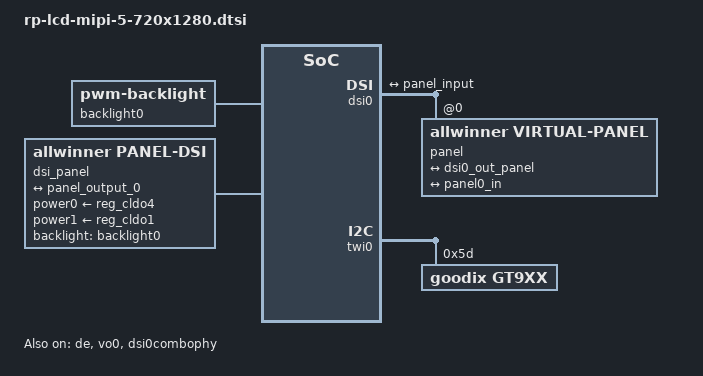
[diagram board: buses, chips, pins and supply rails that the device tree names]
/{
    backlight0: backlight@0 {
        compatible = "pwm-backlight";
        status = "okay";
        brightness-levels = <
              0   1   2   3   4   5   6   7
              8   9  10  11  12  13  14  15
             16  17  18  19  20  21  22  23
             24  25  26  27  28  29  30  31
             32  33  34  35  36  37  38  39
             40  41  42  43  44  45  46  47
             48  49  50  51  52  53  54  55
             56  57  58  59  60  61  62  63
             64  65  66  67  68  69  70  71
             72  73  74  75  76  77  78  79
             80  81  82  83  84  85  86  87
             88  89  90  91  92  93  94  95
             96  97  98  99 100 101 102 103
            104 105 106 107 108 109 110 111
            112 113 114 115 116 117 118 119
            120 121 122 123 124 125 126 127
            128 129 130 131 132 133 134 135
            136 137 138 139 140 141 142 143
            144 145 146 147 148 149 150 151
            152 153 154 155 156 157 158 159
            160 161 162 163 164 165 166 167
            168 169 170 171 172 173 174 175
            176 177 178 179 180 181 182 183
            184 185 186 187 188 189 190 191
            192 193 194 195 196 197 198 199
            200 201 202 203 204 205 206 207
            208 209 210 211 212 213 214 215
            216 217 218 219 220 221 222 223
            224 225 226 227 228 229 230 231
            232 233 234 235 236 237 238 239
            240 241 242 243 244 245 246 247
            248 249 250 251 252 253 254 255>;
        default-brightness-level = <200>;
        // pwms = <&pwm2 0 50000 0>; // config in lcd-gpio-xxx.dtsi
    };

    dsi_panel: dsi_panel@0 {
        compatible = "allwinner,panel-dsi";
        status = "okay";
        reg = <0>;
        power0-supply = <&reg_cldo4>;
        power1-supply = <&reg_cldo1>;

        // reset-gpios = <&pio PJ 17 GPIO_ACTIVE_HIGH>;   // config in lcd-gpio-xxx.dtsi
        // enable0-gpios = <&pio PJ 16 GPIO_ACTIVE_HIGH>; // config in lcd-gpio-xxx.dtsi
        power-delay-ms = <20>;
        enable-delay-ms = <20>;
        reset-num = <1>;
        reset-delay-ms = <20>;

        backlight = <&backlight0>;
        dsi,flags = <MIPI_DSI_MODE_VIDEO>;
        dsi,lanes = <4>;
        dsi,format = <0>; //MIPI_DSI_FMT_RGB888
        panel-init-sequence = [
            39 00 04 B9 F1 12 83
            39 00 0B B3 07 0B 1E 1E 03 FF 00 00 00 00
            39 00 02 BC 46
            39 00 02 CC 0B
            39 00 02 B4 80
            39 00 04 B2 C8 12 A0
            39 00 0F E3 07 07 0B 0B 03 0B 00 00 00 00 FF 80 C0 10
            39 00 0D C1 53 00 32 32 77 F1 FF FF CC CC 77 77
            39 00 03 B5 09 09
            39 00 03 B6 B7 B7
            39 00 40 E9 C2 10 0A 00 00 81 80 12 30 00 37 86 81 80 37 18 00 05 00 00 00 00 00 05 00 00 00 00 F8 BA 46 02 08 28 88 88 88 88 88 F8 BA 57 13 18 38 88 88 88 88 88 00 00 00 03 00 00 00 00 00 00 00 00 00
            39 00 3E EA 07 12 01 01 02 3C 00 00 00 00 00 00 8F BA 31 75 38 18 88 88 88 88 88 8F BA 20 64 28 08 88 88 88 88 88 23 10 00 00 04 00 00 00 00 00 00 00 00 00 00 00 00 00 00 00 00 00 00 00 00 00 00
            39 00 23 E0 00 02 04 1A 23 3F 2C 28 05 09 0B 10 11 10 12 12 19 00 02 04 1A 23 3F 2C 28 05 09 0B 10 11 10 12 12 19
            05 78 01 11
            05 00 01 29
        ];

        panel-exit-sequence = [
            05 14 01 28
            05 50 01 10
        ];

        display-timings {
            native-mode = <&dsi0_timing0>;

            dsi0_timing0: timing0 {
                clock-frequency = <75000000>; /* pixel clock */
                hactive      = <720>;
                hback-porch  = <45>;
                hfront-porch = <136>;
                hsync-len    = <10>;

                vactive      = <1280>;
                vback-porch  = <216>;
                vfront-porch = <16>;
                vsync-len    = <10>;
            };
        };
        port {
            panel0_in: endpoint@0 {
                reg = <0>;
                    remote-endpoint = <&panel_output_0>;
            };
        };
    };
};

&lvds0 {
    status = "disabled";
};

&dsi0 {
    status = "okay";
    pinctrl-0 = <&dsi0_4lane_pins_a>;
    pinctrl-1 = <&dsi0_4lane_pins_b>;
    pinctrl-names = "active","sleep";
    ports {
        dsi0_out: port@1{
            dsi0_out_panel: endpoint {
                remote-endpoint = <&panel_input>;
            };
        };
    };
    panel: panel@0 {
        compatible = "allwinner,virtual-panel";
        status = "okay";
        reg = <0>;
        ports {
            panel_in: port@0 {
                reg = <0>;
                panel_input: endpoint@0 {
                    reg = <0>;
                    remote-endpoint = <&dsi0_out_panel>;
                };
            };
            panel_out: port@1 {
                reg = <1>;
                panel_output_0: endpoint@0 {
                    reg = <0>;
                    remote-endpoint = <&panel0_in>;
                };
            };
        };
    };
};

&de {
    chn_cfg_mode = <3>;
    status = "okay";
};

&vo0 {
    status = "okay";
};

&dsi0combophy {
    status = "okay";
};

&twi0 {
    status = "okay";

    gt9xx: gt9xx@5d {
    };
};

&gt9xx {
    compatible = "goodix,gt9xx";
    reg = <0x5d>;
    status = "okay";

    gtp_resolution_x = <720>;
    gtp_resolution_y = <1280>;
    gtp_int_tarigger = <1>;
    gtp_change_x2y = <0>;
    gtp_overturn_x = <0>;
    gtp_overturn_y = <0>;
    gtp_send_cfg = <1>;
    gtp_touch_wakeup = <1>;
    gtp_touch_back = <1>;
    /*
    our gpio pin config in lcd-gpio-xxx.dtsi
    goodix_rst_gpio = <&pio PB 6 GPIO_ACTIVE_HIGH>;
    goodix_irq_gpio = <&pio PB 7 IRQ_TYPE_EDGE_RISING>;
*/

    goodix,cfg-group0 = [
        4D D0 02 00 05 05 35 00 01 08 32
        08 5A 3C 03 05 00 00 00 00 00 00
        00 18 1A 1E 14 89 29 0A 55 57 B5
        06 00 00 00 41 22 10 00 01 00 0F
        00 2A 00 00 19 50 32 3C 78 94 D5
        02 08 00 00 04 A2 40 00 8F 4A 00
        80 55 00 73 61 00 67 70 00 67 00
        00 00 00 00 00 00 00 00 00 00 00
        00 00 00 00 00 00 00 00 00 00 00
        00 00 00 00 00 00 00 00 00 00 00
        00 00 02 04 06 08 0A 0C 0E 10 12
        14 FF FF FF FF FF FF FF FF FF FF
        FF FF FF FF FF FF FF FF FF FF 22
        21 20 1F 1E 1D 1C 18 16 00 02 04
        06 08 0A 0F 10 12 FF FF FF FF FF
        FF FF FF FF FF FF FF FF FF FF FF
        FF FF FF FF FF FF FF FF 8D 01
    ];
};

